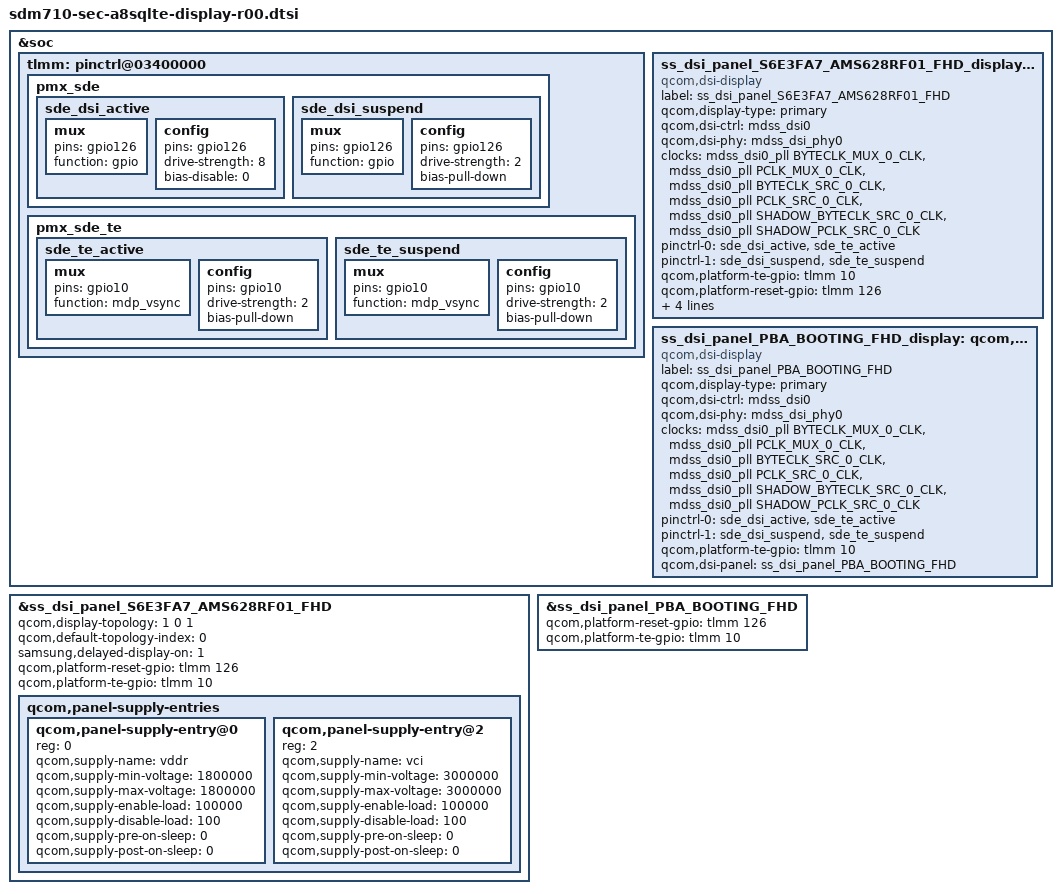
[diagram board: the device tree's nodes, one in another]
/* Copyright (c) 2016-2017, The Linux Foundation. All rights reserved.
 *
 * This program is free software; you can redistribute it and/or modify
 * it under the terms of the GNU General Public License version 2 and
 * only version 2 as published by the Free Software Foundation.
 *
 * This program is distributed in the hope that it will be useful,
 * but WITHOUT ANY WARRANTY; without even the implied warranty of
 * MERCHANTABILITY or FITNESS FOR A PARTICULAR PURPOSE.  See the
 * GNU General Public License for more details.
 */

#include "../../../../drivers/gpu/drm/msm/samsung/S6E3FA7_AMS628RF01/dsi_panel_S6E3FA7_AMS628RF01_fhd_octa_cmd.dtsi"
#include "../../../../drivers/gpu/drm/msm/samsung/PBA_BOOTING/dsi_panel_PBA_BOOTING_fhd_video.dtsi"

&soc {
	tlmm: pinctrl@03400000 {
		pmx_sde: pmx_sde {
			sde_dsi_active: sde_dsi_active {
				mux {
					pins = "gpio126";
					function = "gpio";
				};

				config {
					pins = "gpio126";
					drive-strength = <8>;   /* 8 mA */
					bias-disable = <0>;   /* no pull */
				};
			};
			sde_dsi_suspend: sde_dsi_suspend {
				mux {
					pins = "gpio126";
					function = "gpio";
				};

				config {
					pins = "gpio126";
					drive-strength = <2>;   /* 2 mA */
					bias-pull-down;         /* PULL DOWN */
				};
			};
		};

		pmx_sde_te {
			sde_te_active: sde_te_active {
				mux {
					pins = "gpio10";
					function = "mdp_vsync";
				};

				config {
					pins = "gpio10";
					drive-strength = <2>;   /* 2 mA */
					bias-pull-down;         /* PULL DOWN */
				};
			};

			sde_te_suspend: sde_te_suspend {
				mux {
					pins = "gpio10";
					function = "mdp_vsync";
				};

				config {
					pins = "gpio10";
					drive-strength = <2>;   /* 2 mA */
					bias-pull-down;         /* PULL DOWN */
				};
			};
		};
	};
};

&soc {

	ss_dsi_panel_S6E3FA7_AMS628RF01_FHD_display: qcom,dsi-display@0 {
		compatible = "qcom,dsi-display";
		label = "ss_dsi_panel_S6E3FA7_AMS628RF01_FHD";
		qcom,display-type = "primary";

		qcom,dsi-ctrl = <&mdss_dsi0>;
		qcom,dsi-phy = <&mdss_dsi_phy0>;
		clocks = <&mdss_dsi0_pll BYTECLK_MUX_0_CLK>,
			<&mdss_dsi0_pll PCLK_MUX_0_CLK>,
			<&mdss_dsi0_pll BYTECLK_SRC_0_CLK>,
			<&mdss_dsi0_pll PCLK_SRC_0_CLK>,
			<&mdss_dsi0_pll SHADOW_BYTECLK_SRC_0_CLK>,
			<&mdss_dsi0_pll SHADOW_PCLK_SRC_0_CLK>;
		clock-names = "mux_byte_clk", "mux_pixel_clk",
				"src_byte_clk", "src_pixel_clk",
				"shadow_byte_clk", "shadow_pixel_clk";

		pinctrl-names = "panel_active", "panel_suspend";
		pinctrl-0 = <&sde_dsi_active &sde_te_active>;
		pinctrl-1 = <&sde_dsi_suspend &sde_te_suspend>;
		qcom,platform-te-gpio = <&tlmm 10 0>;
		qcom,platform-reset-gpio = <&tlmm 126 0>;

		qcom,dsi-panel = <&ss_dsi_panel_S6E3FA7_AMS628RF01_FHD>;
		vddr-supply = <&pm660_l11>;
		vci-supply = <&pm660l_l6>;
	};
	/* PBA */
	ss_dsi_panel_PBA_BOOTING_FHD_display: qcom,dsi-display@1 {
		compatible = "qcom,dsi-display";
		label = "ss_dsi_panel_PBA_BOOTING_FHD";
		qcom,display-type = "primary";

		qcom,dsi-ctrl = <&mdss_dsi0>;
		qcom,dsi-phy = <&mdss_dsi_phy0>;

		clocks = <&mdss_dsi0_pll BYTECLK_MUX_0_CLK>,
			<&mdss_dsi0_pll PCLK_MUX_0_CLK>,
			<&mdss_dsi0_pll BYTECLK_SRC_0_CLK>,
			<&mdss_dsi0_pll PCLK_SRC_0_CLK>,
			<&mdss_dsi0_pll SHADOW_BYTECLK_SRC_0_CLK>,
			<&mdss_dsi0_pll SHADOW_PCLK_SRC_0_CLK>;
		clock-names = "mux_byte_clk", "mux_pixel_clk",
				"src_byte_clk", "src_pixel_clk",
				"shadow_byte_clk", "shadow_pixel_clk";

		pinctrl-names = "panel_active", "panel_suspend";
		pinctrl-0 = <&sde_dsi_active &sde_te_active>;   //&sde_ub_det_active>;
		pinctrl-1 = <&sde_dsi_suspend &sde_te_suspend>; //&sde_ub_det_suspend>;
		qcom,platform-te-gpio = <&tlmm 10 0>;

		qcom,dsi-panel = <&ss_dsi_panel_PBA_BOOTING_FHD>;
	};
};

&ss_dsi_panel_S6E3FA7_AMS628RF01_FHD {
	qcom,display-topology = <1 0 1>;
	qcom,default-topology-index = <0>;
	samsung,delayed-display-on = <1>;

	qcom,platform-reset-gpio = <&tlmm 126 0>;
	qcom,platform-te-gpio = <&tlmm 10 0>;
	/delete-property/ qcom,panel-mode-gpio;

	qcom,panel-supply-entries {
		#address-cells = <1>;
		#size-cells = <0>;

		qcom,panel-supply-entry@0 {
		    reg = <0>;
		    qcom,supply-name = "vddr";
		    qcom,supply-min-voltage = <1800000>;
		    qcom,supply-max-voltage = <1800000>;
		    qcom,supply-enable-load = <100000>;
		    qcom,supply-disable-load = <100>;
		    qcom,supply-pre-on-sleep = <0>; /* unit is ms*/
		    qcom,supply-post-on-sleep = <0>;
		};

		qcom,panel-supply-entry@2 {
		    reg = <2>;
		    qcom,supply-name = "vci";
		    qcom,supply-min-voltage = <3000000>;
		    qcom,supply-max-voltage = <3000000>;
		    qcom,supply-enable-load = <100000>;
		    qcom,supply-disable-load = <100>;
		    qcom,supply-pre-on-sleep = <0>; /* unit is ms*/
		    qcom,supply-post-on-sleep = <0>;
		};
	};
};

&ss_dsi_panel_PBA_BOOTING_FHD {
	qcom,platform-reset-gpio = <&tlmm 126 0>;
	qcom,platform-te-gpio = <&tlmm 10 0>;
};

